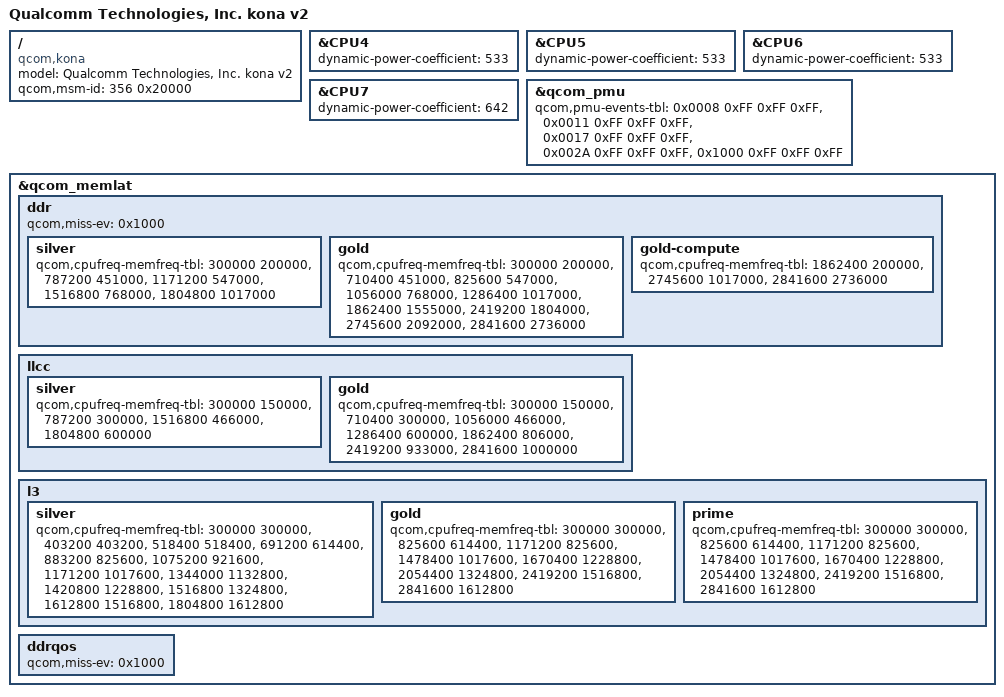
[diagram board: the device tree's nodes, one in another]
#include "kona.dtsi"

/ {
	model = "Qualcomm Technologies, Inc. kona v2";
	compatible = "qcom,kona";
	qcom,msm-id = <356 0x20000>;
};

&CPU4 {
	dynamic-power-coefficient = <533>;
};

&CPU5 {
	dynamic-power-coefficient = <533>;
};

&CPU6 {
	dynamic-power-coefficient = <533>;
};

&CPU7 {
	dynamic-power-coefficient = <642>;
};

&qcom_pmu {
	/delete-property/  qcom,pmu-events-tbl;
	qcom,pmu-events-tbl =
		< 0x0008 0xFF 0xFF 0xFF >,
		< 0x0011 0xFF 0xFF 0xFF >,
		< 0x0017 0xFF 0xFF 0xFF >,
		< 0x002A 0xFF 0xFF 0xFF >,
		< 0x1000 0xFF 0xFF 0xFF >;
};

&qcom_memlat {
	ddr {
		/delete-property/  qcom,miss-ev;
		qcom,miss-ev = <0x1000>;
		silver {
			/delete-property/  qcom,cpufreq-memfreq-tbl;
			qcom,cpufreq-memfreq-tbl =
				<  300000  200000 >,
				<  787200  451000 >,
				< 1171200  547000 >,
				< 1516800  768000 >,
				< 1804800 1017000 >;
		};

		gold {
			/delete-property/  qcom,cpufreq-memfreq-tbl;
			qcom,cpufreq-memfreq-tbl =
				<  300000  200000 >,
				<  710400  451000 >,
				<  825600  547000 >,
				< 1056000  768000 >,
				< 1286400 1017000 >,
				< 1862400 1555000 >,
				< 2419200 1804000 >,
				< 2745600 2092000 >,
				< 2841600 2736000 >;
		};

		gold-compute {
			/delete-property/  qcom,cpufreq-memfreq-tbl;
			qcom,cpufreq-memfreq-tbl =
				< 1862400  200000 >,
				< 2745600 1017000 >,
				< 2841600 2736000 >;
		};
	};

	llcc {
		silver {
			/delete-property/  qcom,cpufreq-memfreq-tbl;
			qcom,cpufreq-memfreq-tbl =
				<  300000  150000 >,
				<  787200  300000 >,
				< 1516800  466000 >,
				< 1804800  600000 >;
		};

		gold {
			/delete-property/  qcom,cpufreq-memfreq-tbl;
			qcom,cpufreq-memfreq-tbl =
				<  300000  150000 >,
				<  710400  300000 >,
				< 1056000  466000 >,
				< 1286400  600000 >,
				< 1862400  806000 >,
				< 2419200  933000 >,
				< 2841600 1000000 >;
		};
	};

	l3 {
		silver {
			/delete-property/  qcom,cpufreq-memfreq-tbl;
			qcom,cpufreq-memfreq-tbl =
				<  300000  300000 >,
				<  403200  403200 >,
				<  518400  518400 >,
				<  691200  614400 >,
				<  883200  825600 >,
				< 1075200  921600 >,
				< 1171200 1017600 >,
				< 1344000 1132800 >,
				< 1420800 1228800 >,
				< 1516800 1324800 >,
				< 1612800 1516800 >,
				< 1804800 1612800 >;
		};

		gold {
			/delete-property/  qcom,cpufreq-memfreq-tbl;
			qcom,cpufreq-memfreq-tbl =
				<  300000  300000 >,
				<  825600  614400 >,
				< 1171200  825600 >,
				< 1478400 1017600 >,
				< 1670400 1228800 >,
				< 2054400 1324800 >,
				< 2419200 1516800 >,
				< 2841600 1612800 >;
		};

		prime {
			/delete-property/  qcom,cpufreq-memfreq-tbl;
			qcom,cpufreq-memfreq-tbl =
				<  300000  300000 >,
				<  825600  614400 >,
				< 1171200  825600 >,
				< 1478400 1017600 >,
				< 1670400 1228800 >,
				< 2054400 1324800 >,
				< 2419200 1516800 >,
				< 2841600 1612800 >;
		};
	};

	ddrqos {
		/delete-property/  qcom,miss-ev;
		qcom,miss-ev = <0x1000>;
	};
};
